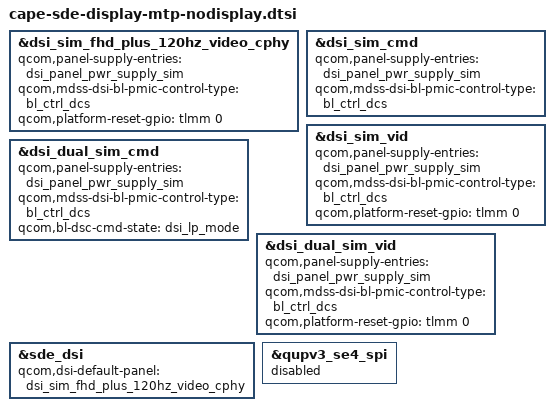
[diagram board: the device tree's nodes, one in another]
#include "cape-sde-display.dtsi"

&dsi_sim_fhd_plus_120hz_video_cphy {
	qcom,panel-supply-entries = <&dsi_panel_pwr_supply_sim>;
	qcom,mdss-dsi-bl-pmic-control-type = "bl_ctrl_dcs";
	qcom,platform-reset-gpio = <&tlmm 0 0>;
};

&dsi_sim_cmd {
	qcom,panel-supply-entries = <&dsi_panel_pwr_supply_sim>;
	qcom,mdss-dsi-bl-pmic-control-type = "bl_ctrl_dcs";
};

&dsi_sim_vid {
	qcom,panel-supply-entries = <&dsi_panel_pwr_supply_sim>;
	qcom,mdss-dsi-bl-pmic-control-type = "bl_ctrl_dcs";
	qcom,platform-reset-gpio = <&tlmm 0 0>;
};

&dsi_dual_sim_cmd {
	qcom,panel-supply-entries = <&dsi_panel_pwr_supply_sim>;
	qcom,mdss-dsi-bl-pmic-control-type = "bl_ctrl_dcs";
	qcom,bl-dsc-cmd-state = "dsi_lp_mode";
};

&dsi_dual_sim_vid {
	qcom,panel-supply-entries = <&dsi_panel_pwr_supply_sim>;
	qcom,mdss-dsi-bl-pmic-control-type = "bl_ctrl_dcs";
	qcom,platform-reset-gpio = <&tlmm 0 0>;
};

&sde_dsi {
	qcom,dsi-default-panel = <&dsi_sim_fhd_plus_120hz_video_cphy>;
};

&qupv3_se4_spi {
	status = "disabled";
};
